# allwinner_xr806_unofficial register map
File version: 1.2
Allwinner's XR806 chip unofficial SVD file
CPU: CM33 r1p2, little endian, MPU, FPU, DSP, vendor SysTick, 8 interrupt priority bits, 8 SAU regions
Registers are 32-bit, read-write, reset 0x0 unless marked. A register's access mark holds for its fields unless they carry their own. Offsets are from the block's base; lines under a group give offsets from that group; [hi:lo] are bit positions; {n}, {i} and the like mark numbered series; 'fields as' and 'values as' point back to an identical list; <NAME> marks a mode.

## Memory map
0x04004000 GPRCM size 0x400
0x40001000 NDMA size 0x1000
0x40004000 SS size 0x1000
0x40005000 SPI0 size 0x1000
0x40009000 DCache_Controller size 0x1000
0x4000A000 SYSCTL size 0x1000
0x4000B000 MEMCTL size 0x1000
0x4000D000 WIFIC size 0x1000
0x40040400 CCM size 0x400
0x40040800 TIMER size 0x400
0x40040C00 UART0 size 0x400
0x40041000 UART1 size 0x400
0x40041400 UART2 size 0x400
0x40041800 RTC size 0x400
0x40041C00 TWI0 size 0x400
0x40042000 TWI1 size 0x400
0x40042800 PWM size 0x400
0x40042C00 DAUDIO size 0x400
0x40043000 GPADC size 0x400
0x40043400 IRTX size 0x400
0x40043800 IRRX size 0x400
0x40043C00 SID size 0x400 — Security ID
0x40044000 AUDIO_PWM size 0x400
0x40044400 TRNG size 0x400
0x40044800 KEYSCAN size 0x400
0x40044C00 ISO7816 size 0x400
0x40045000 FLASH_ENCRYPT size 0x400
0x40045800 LPUART0 size 0x400
0x40045C00 LPUART1 size 0x400
0x40046000 RCOSC_CAL size 0x400
0x40050000 GPIO size 0x400
0x40081000 SDMA size 0x1000
0x4008A000 TZASC size 0x1000

## Interrupts
16 DMA (NDMA)
18 UART0
19 UART1
20 SPI0
21 TWI0
22 TWI1
24 TIMER0 (TIMER)
25 TIMER1 (TIMER)
28 DAUDIO
30 SS
31 GPADC
32 GPIOB (GPIO)
33 IRRX
34 IRTX
37 UART2
39 AUDIO_PWM
44 SMCARD (ISO7816)
45 SDMA
46 LPUART0
47 LPUART1
49 RCCAL (RCOSC_CAL)

## SYSCTL
Base 0x4000A000
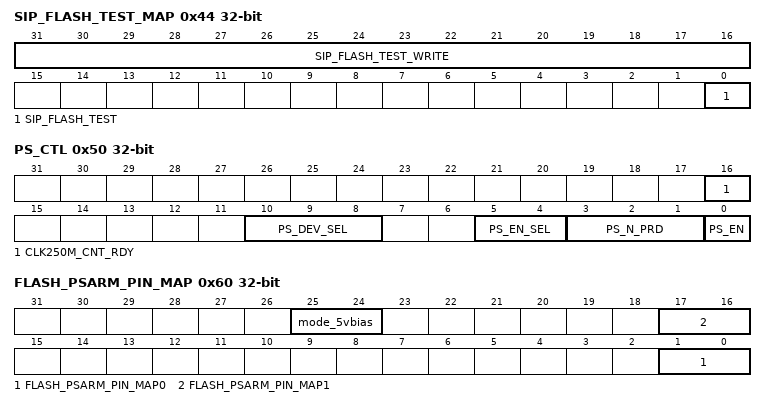
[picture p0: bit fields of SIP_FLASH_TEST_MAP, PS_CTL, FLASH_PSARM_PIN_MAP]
0x44 SIP_FLASH_TEST_MAP — SIP FLASH Test Mapping Register
  [31:16] SIP_FLASH_TEST_WRITE
  [0] SIP_FLASH_TEST
    0=mapping_disabled; 1=mapped_to_external_pins
0x50 PS_CTL — Psensor control register
  [16] CLK250M_CNT_RDY — clk250M counter ready
    0=not_finish; 1=finish
  [10:8] PS_DEV_SEL — psensor device sel
    0=pensor_0; 1=pensor_1
  [5:4] PS_EN_SEL — OSC select
    0=disable; 1=rvt_casecode; 2=lvt_casecode; 3=rvt_normal
  [3:1] PS_N_PRD — clk num period
    0=P4; 1=P8; 2=P16; 3=P32; 4=P64; 5=P128; 6=P256; 7=P512
  [0] PS_EN — psensor enable
    0=disable; 1=enable
0x54 PS_CNT ro — Psensor counter register
  [15:0] CLK250M_CNT — clk 250M counter
0x60 FLASH_PSARM_PIN_MAP — FLASH/PSRAM PIN MAPPING Control Register
  [25:24] mode_5vbias
  [16n+1:16n] FLASH_PSARM_PIN_MAP{n} (n=0..1)
    1=CS0; 2=CS1; 3=CS01
{0xB0+4i} GENERAL_DBG{i} (i=0..1) — General Debug Register
